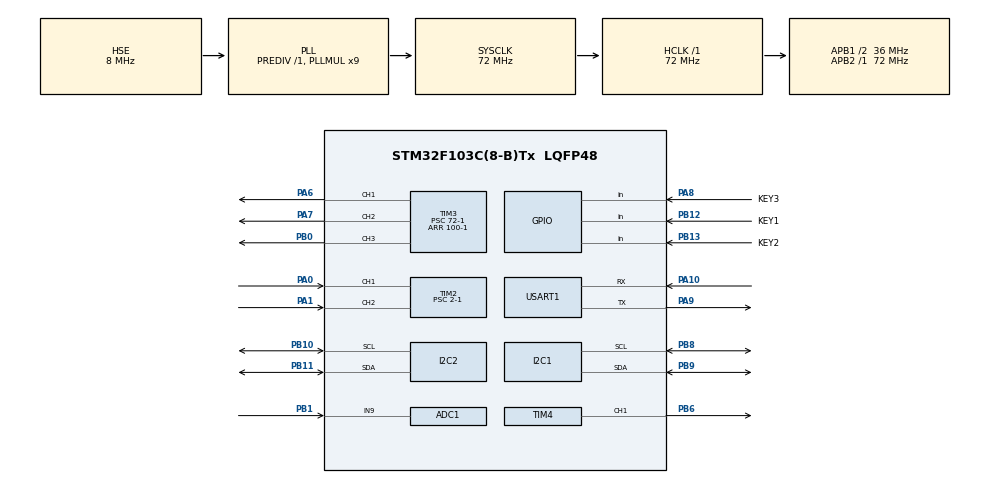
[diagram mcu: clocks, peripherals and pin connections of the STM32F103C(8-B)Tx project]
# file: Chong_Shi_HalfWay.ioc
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ADC1.Channel-3\#ChannelRegularConversion=ADC_CHANNEL_9
ADC1.Channel-4\#ChannelRegularConversion=ADC_CHANNEL_VREFINT
ADC1.NbrOfConversion=2
ADC1.NbrOfConversionFlag=1
ADC1.Rank-3\#ChannelRegularConversion=1
ADC1.Rank-4\#ChannelRegularConversion=2
ADC1.SamplingTime-3\#ChannelRegularConversion=ADC_SAMPLETIME_71CYCLES_5
ADC1.SamplingTime-4\#ChannelRegularConversion=ADC_SAMPLETIME_71CYCLES_5
ADC1.master=1
Dma.Request0=USART1_RX
Dma.Request1=USART1_TX
Dma.USART1_RX.0.Direction=DMA_PERIPH_TO_MEMORY
Dma.USART1_RX.0.Instance=DMA1_Channel5
Dma.USART1_RX.0.MemDataAlignment=DMA_MDATAALIGN_BYTE
Dma.USART1_RX.0.MemInc=DMA_MINC_ENABLE
Dma.USART1_RX.0.Mode=DMA_NORMAL
Dma.USART1_RX.0.PeriphDataAlignment=DMA_PDATAALIGN_BYTE
Dma.USART1_RX.0.PeriphInc=DMA_PINC_DISABLE
Dma.USART1_RX.0.Priority=DMA_PRIORITY_LOW
Dma.USART1_TX.1.Direction=DMA_MEMORY_TO_PERIPH
Dma.USART1_TX.1.Instance=DMA1_Channel4
Dma.USART1_TX.1.MemDataAlignment=DMA_MDATAALIGN_BYTE
Dma.USART1_TX.1.MemInc=DMA_MINC_ENABLE
Dma.USART1_TX.1.Mode=DMA_NORMAL
Dma.USART1_TX.1.PeriphDataAlignment=DMA_PDATAALIGN_BYTE
Dma.USART1_TX.1.PeriphInc=DMA_PINC_DISABLE
Dma.USART1_TX.1.Priority=DMA_PRIORITY_LOW
Mcu.Family=STM32F1
Mcu.Name=STM32F103C(8-B)Tx
Mcu.Package=LQFP48
NVIC.DMA1_Channel4_IRQn=true\:0\:0\:false\:false\:true\:false\:true\:true
NVIC.DMA1_Channel5_IRQn=true\:0\:0\:false\:false\:true\:false\:true\:true
NVIC.PriorityGroup=NVIC_PRIORITYGROUP_4
PA0-WKUP.Signal=S_TIM2_CH1_ETR
PA1.Signal=S_TIM2_CH2
PA10.Mode=Asynchronous
PA10.Signal=USART1_RX
PA13.Mode=Serial_Wire
PA13.Signal=SYS_JTMS-SWDIO
PA14.Mode=Serial_Wire
PA14.Signal=SYS_JTCK-SWCLK
PA6.Signal=S_TIM3_CH1
PA7.Signal=S_TIM3_CH2
PA8.GPIO_Label=KEY3
PA8.GPIO_PuPd=GPIO_PULLDOWN
PA8.Signal=GPIO_Input
PA9.Mode=Asynchronous
PA9.Signal=USART1_TX
PB0.Signal=S_TIM3_CH3
PB1.Signal=ADCx_IN9
PB10.Mode=I2C
PB10.Signal=I2C2_SCL
PB11.Mode=I2C
PB11.Signal=I2C2_SDA
PB12.GPIO_Label=KEY1
PB12.GPIO_PuPd=GPIO_PULLDOWN
PB12.Signal=GPIO_Input
PB13.GPIO_Label=KEY2
PB13.GPIO_PuPd=GPIO_PULLDOWN
PB13.Signal=GPIO_Input
PB6.Signal=S_TIM4_CH1
PB8.Mode=I2C
PB8.Signal=I2C1_SCL
PB9.Mode=I2C
PB9.Signal=I2C1_SDA
PC14-OSC32_IN.Mode=LSE-External-Oscillator
PC14-OSC32_IN.Signal=RCC_OSC32_IN
PC15-OSC32_OUT.Mode=LSE-External-Oscillator
PC15-OSC32_OUT.Signal=RCC_OSC32_OUT
PD0-OSC_IN.Mode=HSE-External-Oscillator
PD0-OSC_IN.Signal=RCC_OSC_IN
PD1-OSC_OUT.Mode=HSE-External-Oscillator
PD1-OSC_OUT.Signal=RCC_OSC_OUT
ProjectManager.HeapSize=0x200
ProjectManager.StackSize=0x400
ProjectManager.TargetToolchain=MDK-ARM V5.32
RCC.ADCPresc=RCC_ADCPCLK2_DIV6
RCC.AHBFreq_Value=72000000
RCC.APB1CLKDivider=RCC_HCLK_DIV2
RCC.APB1Freq_Value=36000000
RCC.APB1TimFreq_Value=72000000
RCC.APB2Freq_Value=72000000
RCC.APB2TimFreq_Value=72000000
RCC.HCLKFreq_Value=72000000
RCC.PLLMUL=RCC_PLL_MUL9
RCC.PLLSourceVirtual=RCC_PLLSOURCE_HSE
RCC.SYSCLKFreq_VALUE=72000000
RCC.SYSCLKSource=RCC_SYSCLKSOURCE_PLLCLK
RCC.USBFreq_Value=72000000
SH.ADCx_IN9.0=ADC1_IN9,IN9
SH.S_TIM2_CH1_ETR.0=TIM2_CH1,Encoder_Interface
SH.S_TIM2_CH2.0=TIM2_CH2,Encoder_Interface
SH.S_TIM3_CH1.0=TIM3_CH1,PWM Generation1 CH1
SH.S_TIM3_CH2.0=TIM3_CH2,PWM Generation2 CH2
SH.S_TIM3_CH3.0=TIM3_CH3,PWM Generation3 CH3
SH.S_TIM4_CH1.0=TIM4_CH1,PWM Generation1 CH1
TIM2.IC1Polarity=TIM_ICPOLARITY_FALLING
TIM2.Prescaler=2-1
TIM3.Channel-PWM\ Generation1\ CH1=TIM_CHANNEL_1
TIM3.Channel-PWM\ Generation2\ CH2=TIM_CHANNEL_2
TIM3.Channel-PWM\ Generation3\ CH3=TIM_CHANNEL_3
TIM3.Period=100-1
TIM3.Prescaler=72-1
TIM3.Pulse-PWM\ Generation3\ CH3=20
TIM4.Channel-PWM\ Generation1\ CH1=TIM_CHANNEL_1
TIM4.Period=2000-1
TIM4.Prescaler=720-1
USART1.VirtualMode=VM_ASYNC
VP_ADC1_Vref_Input.Mode=IN-Vrefint
VP_TIM3_VS_ClockSourceINT.Mode=Internal
board=custom

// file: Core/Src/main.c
/* USER CODE BEGIN Header */
/**
  ******************************************************************************
  * @file           : main.c
  * @brief          : Main program body
  ******************************************************************************
  * @attention
  *
  * Copyright (c) 2026 STMicroelectronics.
  * All rights reserved.
  *
  * This software is licensed under terms that can be found in the LICENSE file
  * in the root directory of this software component.
  * If no LICENSE file comes with this software, it is provided AS-IS.
  *
  ******************************************************************************
  */
/* USER CODE END Header */
#include "main.h"
#include "adc.h"
#include "dma.h"
#include "i2c.h"
#include "tim.h"
#include "usart.h"
#include "gpio.h"

/* USER CODE BEGIN Includes */
#include <stdio.h>
#include <string.h>
#include "oled.h"
#include "EX_oled.h"
/* USER CODE END Includes */

void SystemClock_Config(void);

int main(void)
{

  /* MCU Configuration--------------------------------------------------------*/

  /* Reset of all peripherals, Initializes the Flash interface and the Systick. */
  HAL_Init();

  /* Configure the system clock */
  SystemClock_Config();

  /* Initialize all configured peripherals */
  MX_GPIO_Init();
  MX_DMA_Init();
  MX_TIM3_Init();
  MX_I2C1_Init();
  MX_USART1_UART_Init();
  MX_ADC1_Init();
  MX_I2C2_Init();
  MX_TIM2_Init();
  MX_TIM4_Init();
  /* USER CODE BEGIN 2 */
  HAL_Delay(20);
  OLED_Init();

  // char message[50] = "";

//---------------------{ [ 这个世界上被遗弃的EXIT键 ] }----------------------------------------
  // HAL_GPIO_EXTI_Callback(EXIT_Pin);
  // {
  //   i = 1;
  //   OLED_NewFrame();
  //   OLED_Frame_1(&i);
  //   OLED_ShowFrame();
//-----------中断无需也无法判断按下情况
    // if(HAL_GPIO_ReadPin(EXIT_GPIO_Port,EXIT_Pin))
    // {
    //   HAL_Delay(20);
    //   if(HAL_GPIO_ReadPin(EXIT_GPIO_Port,EXIT_Pin))
    //   {
    //     OLED_Frame_1 ();
    //   }
    // }
  // }

    OLED_PreFrame();
    OLED_Frame_1 ();
    // uint32_t returnning = 0;
    // int* i1 = &i;

  /* USER CODE END 2 */

  /* Infinite loop */
  /* USER CODE BEGIN WHILE */
  while (1)
  {
    // 🤣🤣🤣
    // if(tick_elapsed (&returnning , (uint32_t)20))
    // {
    // READPin();
    // READPinPin();
    // }

    // HAL_GPIO_WritePin(KEY1_GPIO_Port,KEY1_Pin,1);

    /* USER CODE END WHILE */

  }
}

void SystemClock_Config(void)
{
  RCC_OscInitTypeDef RCC_OscInitStruct = {0};
  RCC_ClkInitTypeDef RCC_ClkInitStruct = {0};
  RCC_PeriphCLKInitTypeDef PeriphClkInit = {0};

  /** Initializes the RCC Oscillators according to the specified parameters
  * in the RCC_OscInitTypeDef structure.
  */
  RCC_OscInitStruct.OscillatorType = RCC_OSCILLATORTYPE_HSE;
  RCC_OscInitStruct.HSEState = RCC_HSE_ON;
  RCC_OscInitStruct.HSEPredivValue = RCC_HSE_PREDIV_DIV1;
  RCC_OscInitStruct.HSIState = RCC_HSI_ON;
  RCC_OscInitStruct.PLL.PLLState = RCC_PLL_ON;
  RCC_OscInitStruct.PLL.PLLSource = RCC_PLLSOURCE_HSE;
  RCC_OscInitStruct.PLL.PLLMUL = RCC_PLL_MUL9;
  if (HAL_RCC_OscConfig(&RCC_OscInitStruct) != HAL_OK)
  {
    Error_Handler();
  }

  /** Initializes the CPU, AHB and APB buses clocks
  */
  RCC_ClkInitStruct.ClockType = RCC_CLOCKTYPE_HCLK|RCC_CLOCKTYPE_SYSCLK
                              |RCC_CLOCKTYPE_PCLK1|RCC_CLOCKTYPE_PCLK2;
  RCC_ClkInitStruct.SYSCLKSource = RCC_SYSCLKSOURCE_PLLCLK;
  RCC_ClkInitStruct.AHBCLKDivider = RCC_SYSCLK_DIV1;
  RCC_ClkInitStruct.APB1CLKDivider = RCC_HCLK_DIV2;
  RCC_ClkInitStruct.APB2CLKDivider = RCC_HCLK_DIV1;

  if (HAL_RCC_ClockConfig(&RCC_ClkInitStruct, FLASH_LATENCY_2) != HAL_OK)
  {
    Error_Handler();
  }
  PeriphClkInit.PeriphClockSelection = RCC_PERIPHCLK_ADC;
  PeriphClkInit.AdcClockSelection = RCC_ADCPCLK2_DIV6;
  if (HAL_RCCEx_PeriphCLKConfig(&PeriphClkInit) != HAL_OK)
  {
    Error_Handler();
  }
}

void Error_Handler(void)
{
  __disable_irq();
  while (1)
  {
  }
}
